# PIC32MK0512GPE100 device description
Architecture: MIPS; Family: PIC32MK; Series: PIC32MK
Registers are 32-bit, read-write, no defined reset value unless marked. A register's access mark holds for its fields unless they carry their own. Offsets are from the block's base; [hi:lo] are bit positions; {n}, {i} and the like mark numbered series; 'fields as' and 'values as' point back to an identical list.

## CDAC
Instances: CDAC 0x1f82c200 in periph_pb2_std
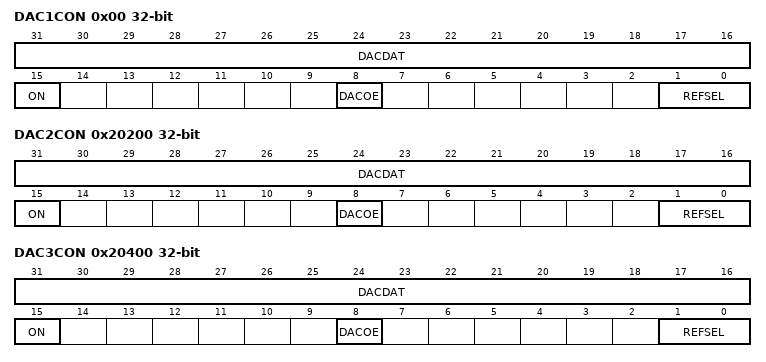
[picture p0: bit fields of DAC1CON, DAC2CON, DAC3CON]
0x00 DAC1CON — CDAC Control Register
  [31:16] DACDAT
  [15] ON — CDAC Enable bit
    1=The CDAC is enabled; 0=The CDAC is disabled
  [8] DACOE — CDAC Output Buffer Enable bit
    1=Output is enabled; CDAC voltage is connected to the pin; 0=Output is disabled; drive to pin is floating
  [1:0] REFSEL — Reference Source Select bits
    3=Positive reference voltage = AVDD; 2=No reference selected (no reference current consumption); 1=No reference selected (no reference current consumption); 0=No reference selected (no reference current consumption)
0x20200 DAC2CON — CDAC Control Register
  fields as DAC1CON
0x20400 DAC3CON — CDAC Control Register
  fields as DAC1CON

## CFG
Instances: CFG 0x1f800000 in periph_pb1_std
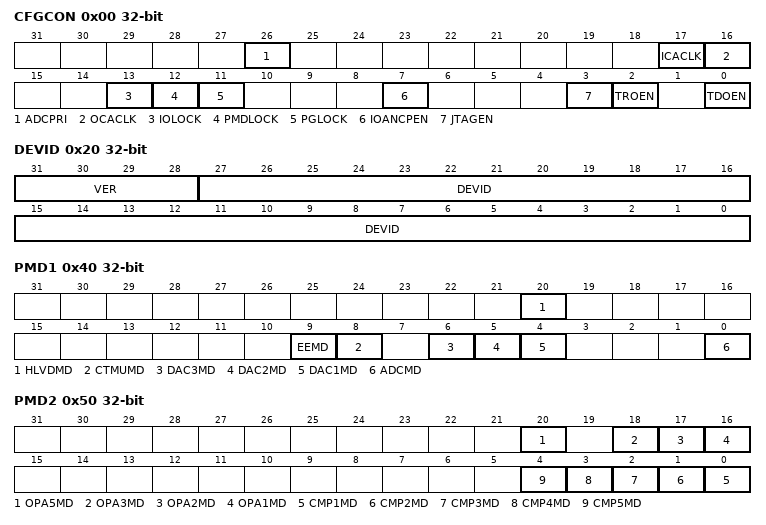
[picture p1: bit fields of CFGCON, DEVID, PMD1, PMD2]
0x00 CFGCON — Configuration Control Register
  [26] ADCPRI — ADC Arbitration Priority to SRAM bit
    1=ADC gets High Priority access to SRAM; 0=ADC uses Least Recently Serviced Arbitration (same as other initiators)
  [17] ICACLK — Input Capture Alternate Clock Selection bit
    1=Input Capture modules use an alternative Timer pair as their timebase clock; 0=All Input Capture modules use Timer2/3 as their timebase clock
  [16] OCACLK — Output Compare Alternate Clock Selection bit
    1=Output Compare modules use an alternative Timer pair as their timebase clock; 0=All Output Compare modules use Timer2/3 as their timebase clock
  [13] IOLOCK — Peripheral Pin Select Lock bit(
    1=Peripheral Pin Select is locked. Writes to PPS registers are not allowed; 0=Peripheral Pin Select is not locked. Writes to PPS registers are allowed
  [12] PMDLOCK — Peripheral Module Disable bit
    1=Peripheral module is locked. Writes to PMD registers are not allowed; 0=Peripheral module is not locked. Writes to PMD registers are allowed
  [11] PGLOCK — Permission Group Lock bit
    1=Permission Group registers are locked. Writes to PG registers are not allowed; 0=Permission Group registers are not locked. Writes to PG registers are allowed
  [7] IOANCPEN — I/O Analog Charge Pump Enable bit
    1=Charge pump is enabled; 0=Charge pump is disabled (default)
  [3] JTAGEN — JTAG Port Enable bit
    1=Enable the JTAG port; 0=Disable the JTAG port
  [2] TROEN — Trace Output Enable bit
    1=Enable trace outputs and start trace clock (trace probe must be present); 0=Disable trace outputs and stop trace clock
  [0] TDOEN — TDO Enable for 2-Wire JTAG
    1=2-wire JTAG protocol uses TDO; 0=2-wire JTAG protocol does not use TDO
0x20 DEVID — Device and Revision ID Register
  [31:28] VER, [27:0] DEVID
0x30 SYSKEY
0x40 PMD1
  [20] HLVDMD, [9] EEMD, [8] CTMUMD, [6] DAC3MD, [5] DAC2MD, [4] DAC1MD, [0] ADCMD
0x50 PMD2
  [20] OPA5MD, [18] OPA3MD, [17] OPA2MD, [16] OPA1MD, [n-1] CMP{n}MD (n=1..5)
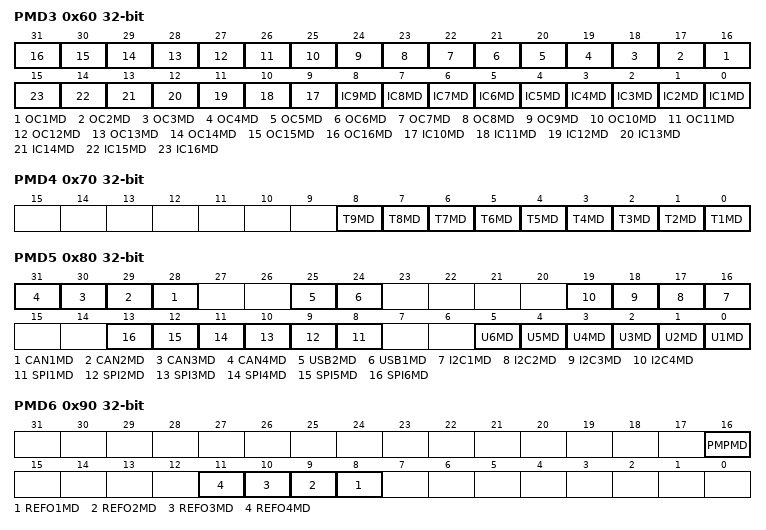
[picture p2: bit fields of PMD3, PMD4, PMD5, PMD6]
0x60 PMD3
  [n+15] OC{n}MD (n=1..16), [n-1] IC{n}MD (n=1..16)
0x70 PMD4
  [n-1] T{n}MD (n=1..9)
0x80 PMD5
  [n+27] CAN{n}MD (n=1..4), [25] USB2MD, [24] USB1MD, [n+15] I2C{n}MD (n=1..4), [n+7] SPI{n}MD (n=1..6), [n-1] U{n}MD (n=1..6)
0x90 PMD6
  [16] PMPMD, [n+7] REFO{n}MD (n=1..4)
0xA0 PMD7
  [4] DMAMD
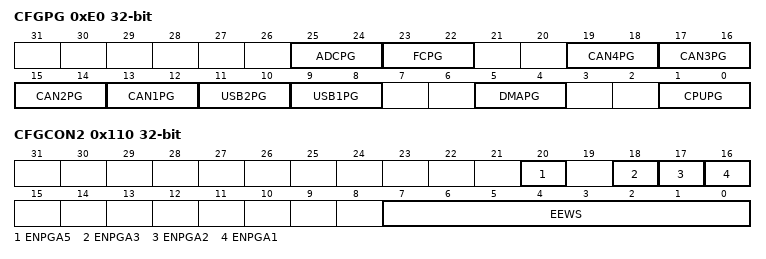
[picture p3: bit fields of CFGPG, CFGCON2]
0xE0 CFGPG — Permission Group Configuration Register
  [25:24] ADCPG — ADC Permission bits
    {v}=Read access if RDPER = 1; write access if WRPER<{v}> = 1 (v=0..3)
  [23:22] FCPG — Flash Control Permission Group bits
    values as ADCPG
  [19:18] CAN4PG
  [17:16] CAN3PG — CAN3 Module Permission Group bits
    values as ADCPG
  [15:14] CAN2PG — CAN2 Module Permission Group bits
    values as ADCPG
  [13:12] CAN1PG — CAN1 Module Permission Group bits
    values as ADCPG
  [11:10] USB2PG — USB2 Module Permission Group bits
    values as ADCPG
  [9:8] USB1PG — USB1 Module Permission Group bits
    values as ADCPG
  [5:4] DMAPG — DMA Module Permission Group bits
    values as ADCPG
  [1:0] CPUPG — CPU Permission Group bits
    values as ADCPG
0x110 CFGCON2 — EE Data and Op amp Configuration Register
  [20] ENPGA5 — Enable Op amp 5 to PGA Mode bit
    1=Op amp enable 1x gain mode; 0=Op amp 3-terminal standard operation (default)
  [18] ENPGA3 — Enable Op amp 3 to PGA Mode bit
    values as ENPGA5
  [17] ENPGA2 — Enable Op amp 2 to PGA Mode bit
    values as ENPGA5
  [16] ENPGA1 — Enable Op amp 1 to PGA Mode bit
    values as ENPGA5
  [7:0] EEWS
Value list DEVID__VER: 0x10000000=Revision A1; 0x20000000=Revision A2

## Notices in the file
Copyright (c) 2017 Microchip Technology Inc.
SPDX-License-Identifier: Apache-2.0
Licensed under the Apache License, Version 2.0 (the "License");
you may not use this file except in compliance with the License.
You may obtain a copy of the License at
http://www.apache.org/licenses/LICENSE-2.0
Unless required by applicable law or agreed to in writing, software
distributed under the License is distributed on an "AS IS" BASIS,
WITHOUT WARRANTIES OR CONDITIONS OF ANY KIND, either express or implied.
See the License for the specific language governing permissions and
limitations under the License.
